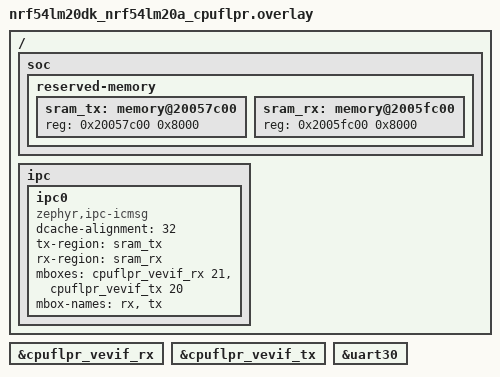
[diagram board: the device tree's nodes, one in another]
/*
 * Copyright (c) 2025 Nordic Semiconductor ASA
 *
 * SPDX-License-Identifier: Apache-2.0
 */

/ {
	soc {
		reserved-memory {
			#address-cells = <1>;
			#size-cells = <1>;

			sram_tx: memory@20057c00 {
				reg = <0x20057c00 0x8000>;
			};

			sram_rx: memory@2005fc00 {
				reg = <0x2005fc00 0x8000>;
			};
		};
	};

	ipc {
		ipc0: ipc0 {
			compatible = "zephyr,ipc-icmsg";
			dcache-alignment = <32>;
			tx-region = <&sram_tx>;
			rx-region = <&sram_rx>;
			mboxes = <&cpuflpr_vevif_rx 21>, <&cpuflpr_vevif_tx 20>;
			mbox-names = "rx", "tx";
			status = "okay";
		};
	};
};

&cpuflpr_vevif_rx {
	status = "okay";
};

&cpuflpr_vevif_tx {
	status = "okay";
};

&uart30 {
	/delete-property/ hw-flow-control;
};
